VERSION ""

NS_ :

BS_:

BU_: XXX  r 6

BO_ 1298 VDC/ABS CAN-ID: 8 XXX
 SG_ Counter : 40|8@1+ (1,0) [0|255] "" XXX
 SG_ Vehicle Speed : 23|16@0+ (0.05625,0) [0|65535] "km/hr" XXX
 SG_ Brake Switch : 36|1@0+ (1,0) [0|1] "" XXX
 SG_ F-Code : 55|16@0+ (1,0) [0|65535] "" XXX
 SG_ VDC Switch : 4|1@0+ (1,0) [0|1] "" XXX

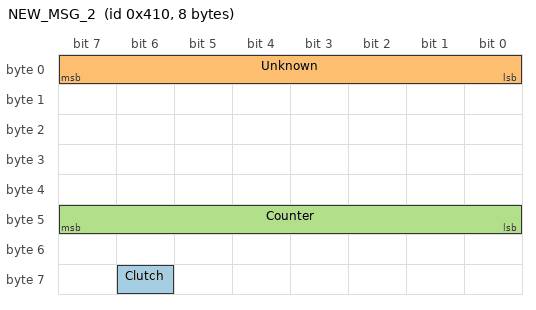
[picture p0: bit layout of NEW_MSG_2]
BO_ 1040 NEW_MSG_2: 8 XXX
 SG_ Engine Torque : 16|8@1+ (1,0) [0|255] "" XXX
 SG_ Torque Loss : 24|8@1+ (1,0) [0|255] "" XXX
 SG_ Accelerator Position : 32|8@1+ (1,0) [0|255] "" XXX
 SG_ Clutch : 62|1@0+ (1,0) [0|1] "" XXX
 SG_ Transmission Torque : 8|8@1+ (1,0) [0|255] "" XXX
 SG_ Unknown : 0|8@1+ (1,0) [0|255] "" XXX
 SG_ Engine Speed : 47|16@0+ (1,0) [0|65535] "" XXX

BO_ 1297 VDC/ABS CAN-ID: 8 XXX
 SG_ Brake Percentage : 32|8@1+ (1,0) [0|255] "" XXX
 SG_ Steering Torque : 23|16@0+ (1,0) [0|65535] "" XXX
 SG_ Steering Wheel Angle : 7|16@0+ (1,0) [0|65535] "" XXX

BO_ 1281 VDC/ABS CAN-ID: 8 XXX
 SG_ Counter : 40|8@1+ (1,0) [0|255] "" XXX

BO_ 1041 ECU CAN-ID: 8 XXX
